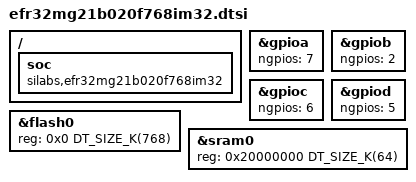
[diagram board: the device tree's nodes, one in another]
/*
 * Copyright (c) 2026 Silicon Laboratories Inc.
 *
 * SPDX-License-Identifier: Apache-2.0
 */

#include <mem.h>
#include <silabs/xg21/efr32mg21.dtsi>

/ {
	soc {
		compatible = "silabs,efr32mg21b020f768im32", "silabs,efr32mg21", "silabs,xg21",
			     "silabs,efr32", "simple-bus";
	};
};

&flash0 {
	reg = <0x0 DT_SIZE_K(768)>;
	ranges = <0x0 0x0 DT_SIZE_K(768)>;
};

&gpioa {
	ngpios = <7>;
};

&gpiob {
	ngpios = <2>;
};

&gpioc {
	ngpios = <6>;
};

&gpiod {
	ngpios = <5>;
};

&sram0 {
	reg = <0x20000000 DT_SIZE_K(64)>;
};
